# AVR16EA48 device description
Architecture: AVR8X; Family: AVR
Registers are 8-bit, read-write, reset 0x0 unless marked. A register's access mark holds for its fields unless they carry their own. Offsets are from the block's base; [hi:lo] are bit positions; {n}, {i} and the like mark numbered series; 'fields as' and 'values as' point back to an identical list.

## PORT — I/O Ports
Instances: PORTA 0x0400, PORTB 0x0420, PORTC 0x0440, PORTD 0x0460, PORTE 0x0480, PORTF 0x04A0
0x00 DIR — Data Direction
0x01 DIRSET — Data Direction Set
0x02 DIRCLR — Data Direction Clear
0x03 DIRTGL — Data Direction Toggle
0x04 OUT — Output Value
0x05 OUTSET — Output Value Set
0x06 OUTCLR — Output Value Clear
0x07 OUTTGL — Output Value Toggle
0x08 IN — Input Value
0x09 INTFLAGS — Interrupt Flags
  [7:0] INT — Pin Interrupt Flag
0x0A PORTCTRL — Port Control
  [0] SRL — Slew Rate Limit Enable
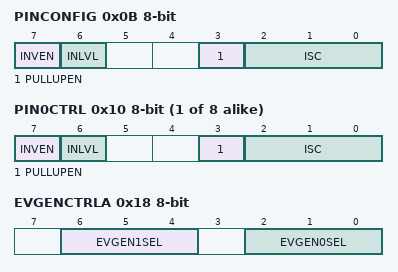
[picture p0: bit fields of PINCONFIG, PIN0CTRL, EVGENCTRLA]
0x0B PINCONFIG — Pin Control Config
  [7] INVEN — Inverted I/O Enable
  [6] INLVL — Input Level Select
    0=ST (Schmitt-Trigger input level); 1=TTL (TTL Input level)
  [3] PULLUPEN — Pullup enable
  [2:0] ISC — Input/Sense Configuration
    0=INTDISABLE (Interrupt disabled but input buffer enabled); 1=BOTHEDGES (Sense Both Edges); 2=RISING (Sense Rising Edge); 3=FALLING (Sense Falling Edge); 4=INPUT_DISABLE (Digital Input Buffer disabled); 5=LEVEL (Sense low Level)
0x0C PINCTRLUPD — Pin Control Update
0x0D PINCTRLSET — Pin Control Set
0x0E PINCTRLCLR — Pin Control Clear
{0x10+i} PIN{i}CTRL (i=0..7) — Pin {i} Control
  fields as PINCONFIG
0x18 EVGENCTRLA — Event Generation Control A
  [6:4] EVGEN1SEL — Event Generator 1 Select
    {v}=PIN{v} (Pin {v} used as event generator) (v=0..7)
  [2:0] EVGEN0SEL — Event Generator 0 Select
    {v}=PIN{v} (Pin {v} used as event generator) (v=0..7)

## PORTMUX — Port Multiplexer
Instances: PORTMUX 0x05E0
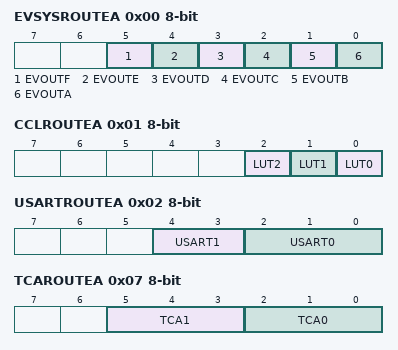
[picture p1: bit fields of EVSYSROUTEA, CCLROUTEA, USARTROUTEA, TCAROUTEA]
0x00 EVSYSROUTEA
  [5] EVOUTF — Event Output F
    0=DEFAULT (EVOUTF: PF2); 1=ALT1 (EVOUTF: PF7)
  [4] EVOUTE — Event Output E
    0=DEFAULT (EVOUTE: PE2)
  [3] EVOUTD — Event Output D
    0=DEFAULT (EVOUTD: PD2); 1=ALT1 (EVOUTD: PD7)
  [2] EVOUTC — Event Output C
    0=DEFAULT (EVOUTC: PC2); 1=ALT1 (EVOUTC: PC7)
  [1] EVOUTB — Event Output B
    0=DEFAULT (EVOUTB: PB2)
  [0] EVOUTA — Event Output A
    0=DEFAULT (EVOUTA: PA2); 1=ALT1 (EVOUTA: PA7)
0x01 CCLROUTEA
  [2] LUT2 — CCL Look-Up Table 2 Signals
    0=DEFAULT (In: PD0, PD1, PD2, Out: PD3); 1=ALT1 (In: PD0, PD1, PD2, Out: PD6)
  [1] LUT1 — CCL Look-Up Table 1 Signals
    0=DEFAULT (In: PC0, PC1, PC2, Out: PC3); 1=ALT1 (In: PC0, PC1, PC2, Out: PC6)
  [0] LUT0 — CCL Look-Up Table 0 Signals
    0=DEFAULT (In: PA0, PA1, PA2, Out: PA3); 1=ALT1 (In: PA0, PA1, PA2, Out: PA6)
0x02 USARTROUTEA
  [4:3] USART1 — USART1 Routing
    0=DEFAULT (TxD: PC0, RxD: PC1, XCK: PC2, XDIR: PC3); 1=ALT1 (TxD: PC4, RxD: PC5, XCK: PC6, XDIR: PC7); 2=ALT2 (TxD: PD6, RxD: PD7, XCK: -, XDIR: -); 3=NONE (Not connected to any pins)
  [2:0] USART0 — USART0 Routing
    0=DEFAULT (TxD: PA0, RxD: PA1, XCK: PA2, XDIR: PA3); 1=ALT1 (TxD: PA4, RxD: PA5, XCK: PA6, XDIR: PA7); 2=ALT2 (TxD: PA2, RxD: PA3, XCK: -, XDIR: -); 3=ALT3 (TxD: PD4, RxD: PD5, XCK: PD6, XDIR: PD7); 4=ALT4 (TxD: PC1, RxD: PC2, XCK: PC3, XDIR: -); 5=NONE (Not connected to any pins)
0x03 USARTROUTEB
  [1:0] USART2 — USART2 Routing
    0=DEFAULT (TxD: PF0, RxD: PF1, XCK: PF2, XDIR: PF3); 1=ALT1 (TxD: PF4, RxD: PF5, XCK: - , XDIR: -); 3=NONE (Not connected to any pins)
0x05 SPIROUTEA
  [2:0] SPI0 — SPI0 Signals
    0=DEFAULT (MOSI: PA4, MISO: PA5, SCK: PA6, SS: PA7); 1=ALT1 (MOSI: PE0, MISO: PE1, SCK: PE2, SS: PE3); 3=ALT3 (MOSI: PA0, MISO: PA1, SCK: PC0, SS: PC1); 4=ALT4 (MOSI: PD4, MISO: PD5, SCK: PD6, SS: PD7); 5=ALT5 (MOSI: PC0, MISO: PC1, SCK: PC2, SS: PC3); 6=ALT6 (MOSI: PC1, MISO: PC2, SCK: PC3, SS: PF7); 7=NONE (Not connected to any pins, SS set to 1)
0x06 TWIROUTEA
  [1:0] TWI0 — TWI0 Signals
    0=DEFAULT (SDA: PA2, SCL: PA3. Dual mode: SDA: PC2, SCL: PC3); 1=ALT1 (SDA: PA2, SCL: PA3. Dual mode: SDA: PC6, SCL: PC7); 2=ALT2 (SDA: PC2, SCL: PC3. Dual mode: SDA: PC6, SCL: PC7); 3=ALT3 (SDA: PA0, SCL: PA1. Dual mode: SDA: PC2, SCL: PC3)
0x07 TCAROUTEA
  [5:3] TCA1 — TCA1 Signals
    0=PORTB (WOn: PB0, PB1, PB2, PB3, PB4, PB5); 1=PORTC (WOn: PC4, PC5, PC6, -, -, -); 4=PORTA (WOn: PA4, PA5, PA6, -, -, -); 5=PORTD (WOn: PD4, PD5, PD6, -, -, -)
  [2:0] TCA0 — TCA0 Signals
    0=PORTA (WOn: PA0, PA1, PA2, PA3, PA4, PA5); 1=PORTB (WOn: PB0, PB1, PB2, PB3, PB4, PB5); 2=PORTC (WOn: PC0, PC1, PC2, PC3, PC4, PC5); 3=PORTD (WOn: PD0, PD1, PD2, PD3, PD4, PD5); 4=PORTE (WOn: PE0, PE1, PE2, PE3, -, -); 5=PORTF (WOn: PF0, PF1, PF2, PF3, PF4, PF5)
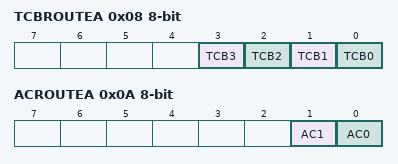
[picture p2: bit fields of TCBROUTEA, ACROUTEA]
0x08 TCBROUTEA
  [3] TCB3 — TCB3 Output
    0=DEFAULT (WO: PB5); 1=ALT1 (WO: PC1)
  [2] TCB2 — TCB2 Output
    0=DEFAULT (WO: PC0); 1=ALT1 (WO: PB4)
  [1] TCB1 — TCB1 Output
    0=DEFAULT (WO: PA3); 1=ALT1 (WO: PF5)
  [0] TCB0 — TCB0 Output
    0=DEFAULT (WO: PA2); 1=ALT1 (WO: PF4)
0x0A ACROUTEA
  [1] AC1 — Analog Comparator 1 Output
    0=DEFAULT (OUT: PA7); 1=ALT1 (OUT: PC6)
  [0] AC0 — Analog Comparator 0 Output
    0=DEFAULT (OUT: PA7); 1=ALT1 (OUT: PC6)
